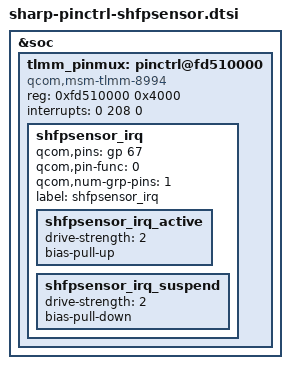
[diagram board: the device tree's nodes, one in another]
/* Copyright (c) 2015, The Linux Foundation. All rights reserved.
 *
 * This program is free software; you can redistribute it and/or modify
 * it under the terms of the GNU General Public License version 2 and
 * only version 2 as published by the Free Software Foundation.
 *
 * This program is distributed in the hope that it will be useful,
 * but WITHOUT ANY WARRANTY; without even the implied warranty of
 * MERCHANTABILITY or FITNESS FOR A PARTICULAR PURPOSE.  See the
 * GNU General Public License for more details.
 */

&soc {
	tlmm_pinmux: pinctrl@fd510000 {
		compatible = "qcom,msm-tlmm-8994", "qcom,msm-tlmm-8974";
		reg = <0xfd510000 0x4000>;
		interrupts = <0 208 0>;

		/*****************************************/
		/*  pinctrl customize setting            */
		/*****************************************/
		shfpsensor_irq {
			/* GPIO_67 */
			qcom,pins = <&gp 67>;
			qcom,pin-func = <0>;
			qcom,num-grp-pins = <1>;
			label = "shfpsensor_irq";

			shfpsensor_irq_active: shfpsensor_irq_active {
				drive-strength = <2>;
				bias-pull-up;
			};

			shfpsensor_irq_suspend: shfpsensor_irq_suspend {
				drive-strength = <2>;
				bias-pull-down;
			};
		};

	};
};

